# EFR32FG22C121F256GM32 register map
Vendor: Silicon Labs; Series: EFR32; File version: C
Registers are 32-bit, read-write, reset 0x0 unless marked. A register's access mark holds for its fields unless they carry their own. Offsets are from the block's base; [hi:lo] are bit positions; {n}, {i} and the like mark numbered series.

## RTCC_S — RTCC_S Registers
Base 0x48000000
Same registers: RTCC_NS 0x58000000
0x00 IPVERSION ro reset 0x1
0x04 EN
  [0] EN — RTCC Enable
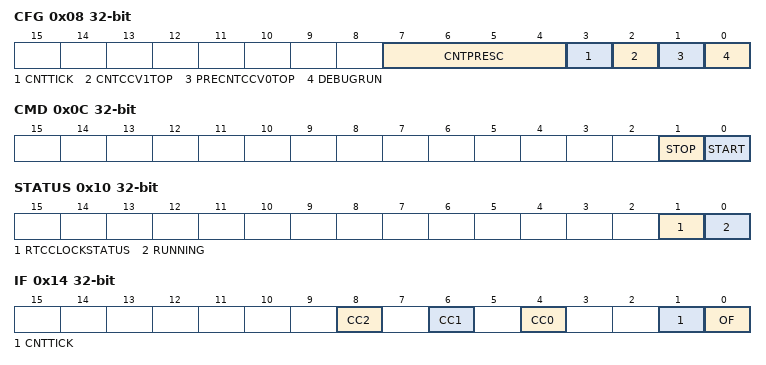
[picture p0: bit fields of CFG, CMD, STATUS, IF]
0x08 CFG
  [7:4] CNTPRESC — Counter prescaler value.
    0=DIV1 (CLK_CNT = (RTCC LF CLK)/1); 1=DIV2 (CLK_CNT = (RTCC LF CLK)/2); 2=DIV4 (CLK_CNT = (RTCC LF CLK)/4); 3=DIV8 (CLK_CNT = (RTCC LF CLK)/8); 4=DIV16 (CLK_CNT = (RTCC LF CLK)/16); 5=DIV32 (CLK_CNT = (RTCC LF CLK)/32); 6=DIV64 (CLK_CNT = (RTCC LF CLK)/64); 7=DIV128 (CLK_CNT = (RTCC LF CLK)/128); 8=DIV256 (CLK_CNT = (RTCC LF CLK)/256); 9=DIV512 (CLK_CNT = (RTCC LF CLK)/512); 10=DIV1024 (CLK_CNT = (RTCC LF CLK)/1024); 11=DIV2048 (CLK_CNT = (RTCC LF CLK)/2048); 12=DIV4096 (CLK_CNT = (RTCC LF CLK)/4096); 13=DIV8192 (CLK_CNT = (RTCC LF CLK)/8192); 14=DIV16384 (CLK_CNT = (RTCC LF CLK)/16384); 15=DIV32768 (CLK_CNT = (RTCC LF CLK)/32768)
  [3] CNTTICK — Counter prescaler mode.
    0=PRESC (CNT register ticks according to configuration in CNTPRESC.); 1=CCV0MATCH (CNT register ticks when PRECNT matches RTCC_CC0_OC[14:0])
  [2] CNTCCV1TOP — CCV1 top value enable
  [1] PRECNTCCV0TOP — Pre-counter CCV0 top value enable.
  [0] DEBUGRUN — Debug Mode Run Enable
    0=RTCC is frozen in debug mode; 1=RTCC is running in debug mode
0x0C CMD wo
  [1] STOP — Stop RTCC main counter
  [0] START — Start RTCC main counter
0x10 STATUS ro
  [1] RTCCLOCKSTATUS — Lock Status
    0=UNLOCKED (RTCC registers are unlocked); 1=LOCKED (RTCC registers are locked)
  [0] RUNNING — RTCC running status
0x14 IF
  [8] CC2 — CC Channel n Interrupt Flag
  [6] CC1 — CC Channel n Interrupt Flag
  [4] CC0 — CC Channel n Interrupt Flag
  [1] CNTTICK — Main counter tick
  [0] OF — Overflow Interrupt Flag
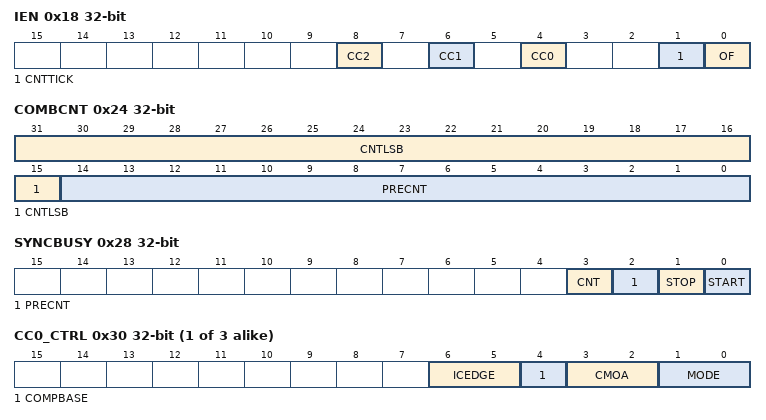
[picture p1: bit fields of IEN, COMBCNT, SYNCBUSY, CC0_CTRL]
0x18 IEN
  [8] CC2 — CC Channel n Interrupt Enable
  [6] CC1 — CC Channel n Interrupt Enable
  [4] CC0 — CC Channel n Interrupt Enable
  [1] CNTTICK — CNTTICK Interrupt Enable
  [0] OF — OF Interrupt Enable
0x1C PRECNT
  [14:0] PRECNT — Pre-Counter Value
0x20 CNT
  [31:0] CNT — Counter Value
0x24 COMBCNT ro
  [31:15] CNTLSB — Counter Value
  [14:0] PRECNT — Pre-Counter Value
0x28 SYNCBUSY ro
  [3] CNT — Sync busy for CNT
  [2] PRECNT — Sync busy for PRECNT
  [1] STOP — Sync busy for STOP
  [0] START — Sync busy for START
0x2C LOCK wo
  [15:0] LOCKKEY — Configuration Lock Key
    0xAEE8=UNLOCK (Write to unlock RTCC lockable registers)
{0x30+0xC*i} CC{i}_CTRL (i=0..2)
  [6:5] ICEDGE — Input Capture Edge Select
    0=RISING (Rising edges detected); 1=FALLING (Falling edges detected); 2=BOTH (Both edges detected); 3=NONE (No edge detection, signal is left as it is)
  [4] COMPBASE — Capture compare channel comparison base.
    0=CNT (RTCC_CCx_ICVALUE/OCVALUE is compared with CNT register.); 1=PRECNT (Least significant bits of RTCC_CCx_ICVALUE/OCVALUE are compared with COMBCNT.)
  [3:2] CMOA — Compare Match Output Action
    0=PULSE (A single clock cycle pulse is generated on output); 1=TOGGLE (Toggle output on compare match); 2=CLEAR (Clear output on compare match); 3=SET (Set output on compare match)
  [1:0] MODE — CC Channel Mode
    0=OFF (Compare/Capture channel turned off); 1=INPUTCAPTURE; 2=OUTPUTCOMPARE
{0x34+0xC*i} CC{i}_OCVALUE (i=0..2)
  [31:0] OC — Output Compare Value
{0x38+0xC*i} CC{i}_ICVALUE ro (i=0..2)
  [31:0] IC — Input Capture Value

## PRORTC_S — PRORTC_S Registers
Base 0xA8000000
Same registers: PRORTC_NS 0xB8000000
Registers as RTCC_S, without CC2_CTRL, CC2_OCVALUE, CC2_ICVALUE; these are added or differ:
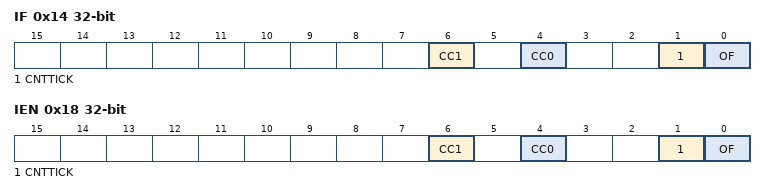
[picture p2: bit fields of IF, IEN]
0x14 IF
  [6] CC1 — CC Channel n Interrupt Flag
  [4] CC0 — CC Channel n Interrupt Flag
  [1] CNTTICK — Main counter tick
  [0] OF — Overflow Interrupt Flag
0x18 IEN
  [6] CC1 — CC Channel n Interrupt Enable
  [4] CC0 — CC Channel n Interrupt Enable
  [1] CNTTICK — CNTTICK Interrupt Enable
  [0] OF — OF Interrupt Enable
